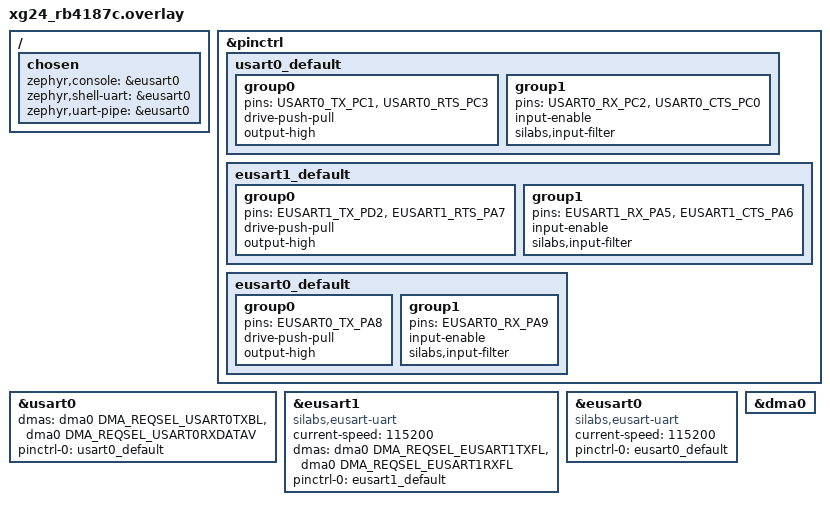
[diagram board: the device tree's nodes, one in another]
/*
 * Copyright (c) 2026, Silicon Laboratories Inc.
 *
 * SPDX-License-Identifier: Apache-2.0
 */

/*
 * Connect EXP[4,6,8,10] with EXP[7,9,11,13] on the Expension Pin header
 */
/ {
	chosen {
		zephyr,console = &eusart0;
		zephyr,shell-uart = &eusart0;
		zephyr,uart-pipe = &eusart0;
	};
};

&pinctrl {
	usart0_default: usart0_default {
		group0 {
			pins = <USART0_TX_PC1>, <USART0_RTS_PC3>;
			drive-push-pull;
			output-high;
		};

		group1 {
			pins = <USART0_RX_PC2>, <USART0_CTS_PC0>;
			input-enable;
			silabs,input-filter;
		};
	};

	eusart1_default: eusart1_default {
		group0 {
			pins = <EUSART1_TX_PD2>, <EUSART1_RTS_PA7>;
			drive-push-pull;
			output-high;
		};

		group1 {
			pins = <EUSART1_RX_PA5>, <EUSART1_CTS_PA6>;
			input-enable;
			silabs,input-filter;
		};
	};

	eusart0_default: eusart0_default {
		group0 {
			pins = <EUSART0_TX_PA8>;
			drive-push-pull;
			output-high;
		};

		group1 {
			pins = <EUSART0_RX_PA9>;
			input-enable;
			silabs,input-filter;
		};
	};
};

dut: &usart0 {
	dmas = <&dma0 DMA_REQSEL_USART0TXBL>,
	       <&dma0 DMA_REQSEL_USART0RXDATAV>;
	dma-names = "tx", "rx";
	pinctrl-0 = <&usart0_default>;
	pinctrl-names = "default";
};

dut_aux: &eusart1 {
	compatible = "silabs,eusart-uart";
	current-speed = <115200>;
	dmas = <&dma0 DMA_REQSEL_EUSART1TXFL>,
	       <&dma0 DMA_REQSEL_EUSART1RXFL>;
	dma-names = "tx", "rx";
	pinctrl-0 = <&eusart1_default>;
	pinctrl-names = "default";
	status = "okay";

	/delete-property/ cs-gpios;
};

&eusart0 {
	compatible = "silabs,eusart-uart";
	current-speed = <115200>;
	pinctrl-0 = <&eusart0_default>;
	pinctrl-names = "default";
	status = "okay";
};

&dma0 {
	status = "okay";
};
